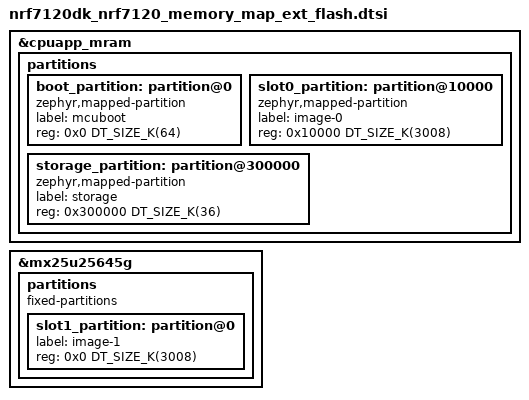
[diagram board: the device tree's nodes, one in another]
/*
 * Copyright (c) 2026 Nordic Semiconductor ASA
 *
 * SPDX-License-Identifier: LicenseRef-Nordic-5-Clause
 */

/*
 * Memory map with the MCUboot secondary slot placed in the external
 * MX25U25645G flash connected to MSPI00:
 *
 * MRAM:
 *   0x0000_0000 MCUboot (64 KB)
 *   0x0001_0000 Primary image slot (3008 KB)
 *   0x0030_0000 Storage (36 KB)
 *
 * External flash:
 *   0x0000_0000 Secondary image slot (3008 KB)
 */

/delete-node/ &boot_partition;
/delete-node/ &slot0_partition;
/delete-node/ &slot1_partition;
/delete-node/ &storage_partition;

&cpuapp_mram {
	partitions {
		boot_partition: partition@0 {
			compatible = "zephyr,mapped-partition";
			label = "mcuboot";
			reg = <0x0 DT_SIZE_K(64)>;
		};

		slot0_partition: partition@10000 {
			compatible = "zephyr,mapped-partition";
			label = "image-0";
			reg = <0x10000 DT_SIZE_K(3008)>;
		};

		storage_partition: partition@300000 {
			compatible = "zephyr,mapped-partition";
			label = "storage";
			reg = <0x300000 DT_SIZE_K(36)>;
		};
	};
};

&mx25u25645g {
	partitions {
		compatible = "fixed-partitions";
		#address-cells = <1>;
		#size-cells = <1>;

		slot1_partition: partition@0 {
			label = "image-1";
			reg = <0x0 DT_SIZE_K(3008)>;
		};
	};
};
